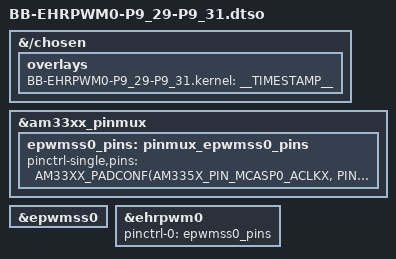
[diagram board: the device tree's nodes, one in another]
// SPDX-License-Identifier: GPL-2.0-only
/*
 * Copyright (C) 2025 Robert Nelson <robertcnelson@gmail.com>
 */

/dts-v1/;
/plugin/;

#include <dt-bindings/pinctrl/am33xx.h>

/*
 * Helper to show loaded overlays under: /proc/device-tree/chosen/overlays/
 */
&{/chosen} {
	overlays {
		BB-EHRPWM0-P9_29-P9_31.kernel = __TIMESTAMP__;
	};
};

&am33xx_pinmux {
	epwmss0_pins: pinmux_epwmss0_pins {
		pinctrl-single,pins = <
			AM33XX_PADCONF(AM335X_PIN_MCASP0_ACLKX, PIN_OUTPUT, MUX_MODE1) /* P9_31 ehrpwm0A */
			AM33XX_PADCONF(AM335X_PIN_MCASP0_FSX, PIN_OUTPUT, MUX_MODE1) /* P9_29 ehrpwm0B */
		>;
	};
};

&epwmss0 {
	status = "okay";
};

&ehrpwm0 {
	status = "okay";
	pinctrl-names = "default";
	pinctrl-0 = <&epwmss0_pins>;
};
